VERSION ""

NS_ :

BS_:

BU_: VCU ECUMASTER_GPS_IMU

BO_ 1024 ECUMASTER_GPS_IMU_0: 8 ECUMASTER_GPS_IMU
 SG_ LATITUDE : 7|32@0- (1e-7,0) [-90|90] "deg" Vector__XXX
 SG_ LONGITUDE : 39|32@0- (1e-7,0) [-180|180] "deg" Vector__XXX

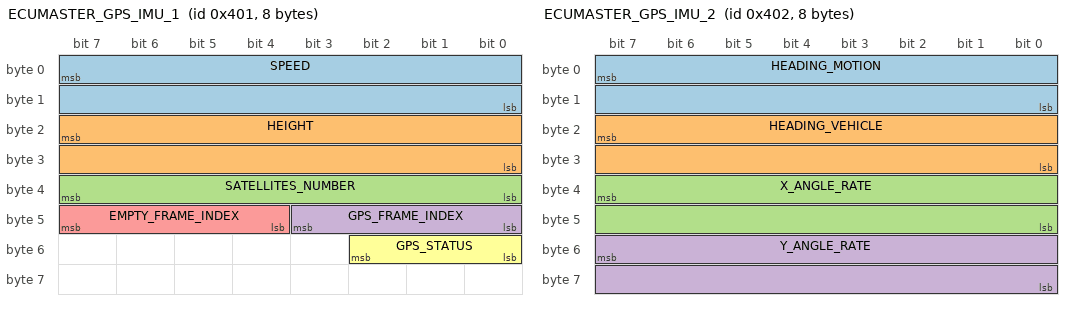
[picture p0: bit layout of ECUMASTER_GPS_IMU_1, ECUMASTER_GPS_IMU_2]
BO_ 1025 ECUMASTER_GPS_IMU_1: 8 ECUMASTER_GPS_IMU
 SG_ SPEED : 7|16@0- (0.036,0) [-1179|1179] "km/h" Vector__XXX
 SG_ HEIGHT : 23|16@0- (1,0) [-32768|32767] "m" Vector__XXX
 SG_ SATELLITES_NUMBER : 39|8@0+ (1,0) [0|72] "" Vector__XXX
 SG_ GPS_FRAME_INDEX : 43|4@0+ (1,0) [0|16] "" Vector__XXX
 SG_ EMPTY_FRAME_INDEX : 47|4@0+ (1,0) [0|16] "" Vector__XXX
 SG_ GPS_STATUS : 50|3@0+ (1,0) [1|5] "" Vector__XXX

BO_ 1026 ECUMASTER_GPS_IMU_2: 8 ECUMASTER_GPS_IMU
 SG_ HEADING_MOTION : 7|16@0+ (1,0) [0|360] "deg" Vector__XXX
 SG_ HEADING_VEHICLE : 23|16@0+ (1,0) [0|360] "deg" Vector__XXX
 SG_ X_ANGLE_RATE : 39|16@0- (0.01,0) [-250|250] "deg/s" Vector__XXX
 SG_ Y_ANGLE_RATE : 55|16@0- (0.01,0) [-250|250] "deg/s" Vector__XXX

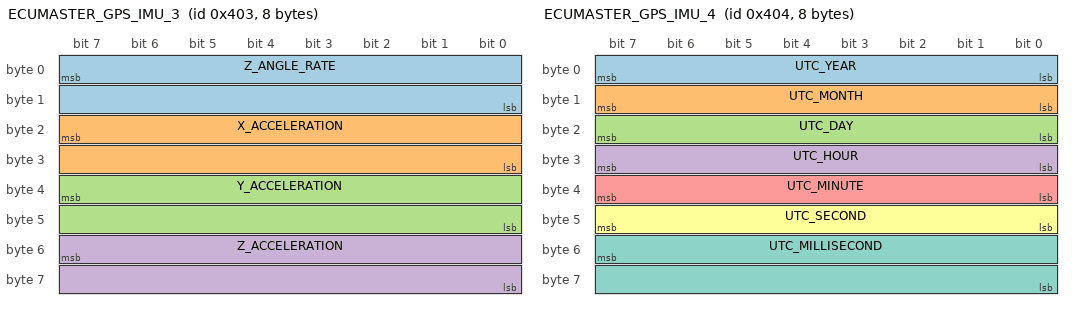
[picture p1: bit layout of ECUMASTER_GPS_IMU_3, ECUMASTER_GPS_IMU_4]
BO_ 1027 ECUMASTER_GPS_IMU_3: 8 ECUMASTER_GPS_IMU
 SG_ Z_ANGLE_RATE : 7|16@0- (0.01,0) [-250|250] "deg/s" Vector__XXX
 SG_ X_ACCELERATION : 23|16@0- (0.01,0) [-4|4] "g" Vector__XXX
 SG_ Y_ACCELERATION : 39|16@0- (0.01,0) [-4|4] "g" Vector__XXX
 SG_ Z_ACCELERATION : 55|16@0- (0.01,0) [-4|4] "g" Vector__XXX

BO_ 1028 ECUMASTER_GPS_IMU_4: 8 ECUMASTER_GPS_IMU
 SG_ UTC_YEAR : 7|8@0+ (1,2000) [2000|2255] "years" Vector__XXX
 SG_ UTC_MONTH : 15|8@0+ (1,0) [1|12] "months" Vector__XXX
 SG_ UTC_DAY : 23|8@0+ (1,0) [1|31] "days" Vector__XXX
 SG_ UTC_HOUR : 31|8@0+ (1,0) [0|23] "hours" Vector__XXX
 SG_ UTC_MINUTE : 39|8@0+ (1,0) [0|59] "minutes" Vector__XXX
 SG_ UTC_SECOND : 47|8@0+ (1,0) [0|59] "s" Vector__XXX
 SG_ UTC_MILLISECOND : 55|16@0+ (0.0152587890625,0) [0|999.99] "ms" Vector__XXX

CM_ SG_ 1026 HEADING_MOTION "TODO(Barach): The scalar on this is listed as 1, but this is likely wrong.";
CM_ SG_ 1026 HEADING_VEHICLE "TODO(Barach): The scalar on this is listed as 1, but this is likely wrong.";

BA_DEF_  "BusType" STRING ;
BA_DEF_DEF_  "BusType" "CAN";
